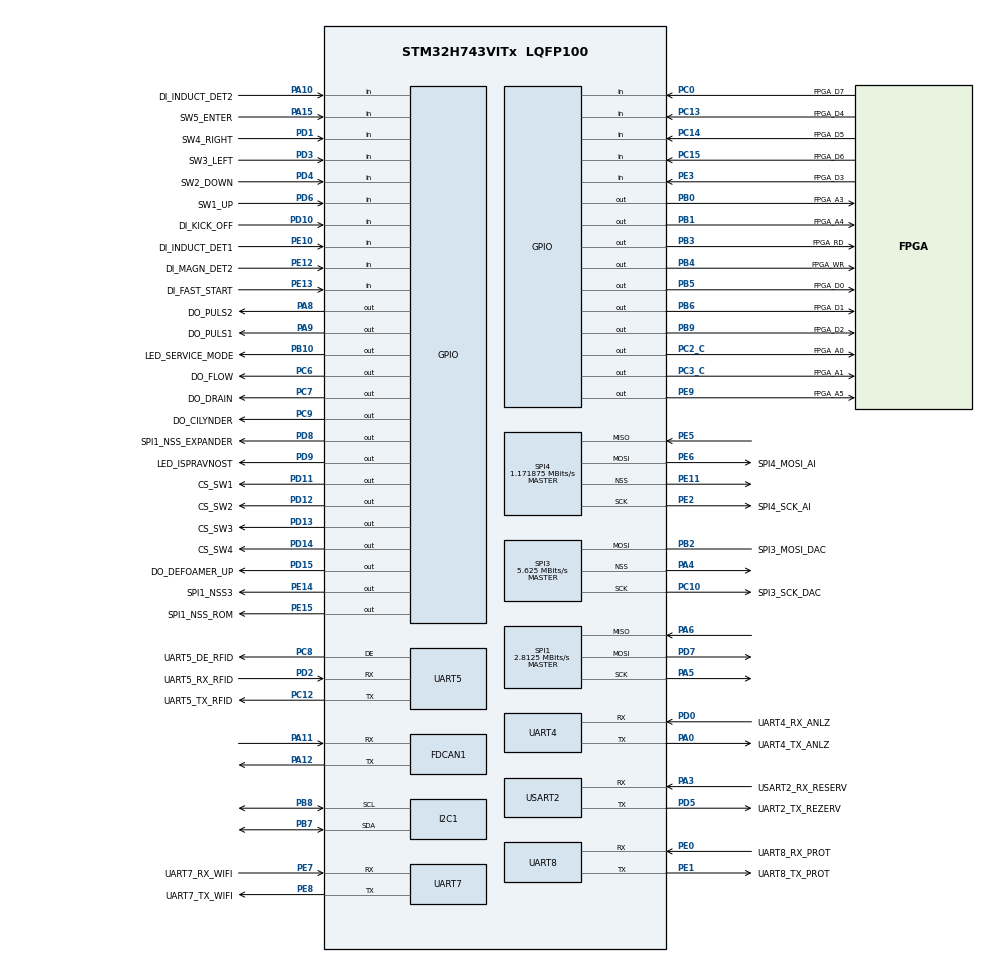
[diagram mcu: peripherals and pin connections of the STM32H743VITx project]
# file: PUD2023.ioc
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Dma.Request0=SPI3_TX
Dma.Request1=SPI4_RX
Dma.Request2=SPI4_TX
Dma.SPI3_TX.0.Direction=DMA_MEMORY_TO_PERIPH
Dma.SPI3_TX.0.EventEnable=DISABLE
Dma.SPI3_TX.0.FIFOMode=DMA_FIFOMODE_DISABLE
Dma.SPI3_TX.0.Instance=DMA1_Stream0
Dma.SPI3_TX.0.MemDataAlignment=DMA_MDATAALIGN_HALFWORD
Dma.SPI3_TX.0.MemInc=DMA_MINC_ENABLE
Dma.SPI3_TX.0.Mode=DMA_CIRCULAR
Dma.SPI3_TX.0.PeriphDataAlignment=DMA_PDATAALIGN_HALFWORD
Dma.SPI3_TX.0.PeriphInc=DMA_PINC_DISABLE
Dma.SPI3_TX.0.Polarity=HAL_DMAMUX_REQ_GEN_RISING
Dma.SPI3_TX.0.Priority=DMA_PRIORITY_LOW
Dma.SPI3_TX.0.RequestNumber=1
Dma.SPI3_TX.0.SignalID=NONE
Dma.SPI3_TX.0.SyncEnable=ENABLE
Dma.SPI3_TX.0.SyncPolarity=HAL_DMAMUX_SYNC_RISING
Dma.SPI3_TX.0.SyncRequestNumber=1
Dma.SPI3_TX.0.SyncSignalID=HAL_DMAMUX1_SYNC_TIM12_TRGO
Dma.SPI4_RX.1.Direction=DMA_PERIPH_TO_MEMORY
Dma.SPI4_RX.1.EventEnable=DISABLE
Dma.SPI4_RX.1.FIFOMode=DMA_FIFOMODE_DISABLE
Dma.SPI4_RX.1.Instance=DMA1_Stream1
Dma.SPI4_RX.1.MemDataAlignment=DMA_MDATAALIGN_BYTE
Dma.SPI4_RX.1.MemInc=DMA_MINC_ENABLE
Dma.SPI4_RX.1.Mode=DMA_NORMAL
Dma.SPI4_RX.1.PeriphDataAlignment=DMA_PDATAALIGN_BYTE
Dma.SPI4_RX.1.PeriphInc=DMA_PINC_DISABLE
Dma.SPI4_RX.1.Polarity=HAL_DMAMUX_REQ_GEN_RISING
Dma.SPI4_RX.1.Priority=DMA_PRIORITY_LOW
Dma.SPI4_RX.1.RequestNumber=1
Dma.SPI4_RX.1.SignalID=NONE
Dma.SPI4_RX.1.SyncEnable=DISABLE
Dma.SPI4_RX.1.SyncPolarity=HAL_DMAMUX_SYNC_NO_EVENT
Dma.SPI4_RX.1.SyncRequestNumber=1
Dma.SPI4_RX.1.SyncSignalID=NONE
Dma.SPI4_TX.2.Direction=DMA_MEMORY_TO_PERIPH
Dma.SPI4_TX.2.EventEnable=DISABLE
Dma.SPI4_TX.2.FIFOMode=DMA_FIFOMODE_DISABLE
Dma.SPI4_TX.2.Instance=DMA1_Stream2
Dma.SPI4_TX.2.MemDataAlignment=DMA_MDATAALIGN_BYTE
Dma.SPI4_TX.2.MemInc=DMA_MINC_ENABLE
Dma.SPI4_TX.2.Mode=DMA_NORMAL
Dma.SPI4_TX.2.PeriphDataAlignment=DMA_PDATAALIGN_BYTE
Dma.SPI4_TX.2.PeriphInc=DMA_PINC_DISABLE
Dma.SPI4_TX.2.Polarity=HAL_DMAMUX_REQ_GEN_RISING
Dma.SPI4_TX.2.Priority=DMA_PRIORITY_LOW
Dma.SPI4_TX.2.RequestNumber=1
Dma.SPI4_TX.2.SignalID=NONE
Dma.SPI4_TX.2.SyncEnable=DISABLE
Dma.SPI4_TX.2.SyncPolarity=HAL_DMAMUX_SYNC_NO_EVENT
Dma.SPI4_TX.2.SyncRequestNumber=1
Dma.SPI4_TX.2.SyncSignalID=NONE
FDCAN1.CalculateBaudRateNominal=1000000
FDCAN1.CalculateTimeBitNominal=1000
FDCAN1.CalculateTimeQuantumNominal=50.0
FDCAN1.Mode=FDCAN_MODE_INTERNAL_LOOPBACK
FDCAN1.NominalPrescaler=2
FDCAN1.NominalTimeSeg1=15
FDCAN1.NominalTimeSeg2=4
FDCAN1.RxFifo0ElmtsNbr=64
FDCAN1.TxFifoQueueElmtsNbr=32
FDCAN1.TxFifoQueueMode=FDCAN_TX_QUEUE_OPERATION
I2C1.Timing=0x109093DC
Mcu.Family=STM32H7
Mcu.Name=STM32H743VITx
Mcu.Package=LQFP100
NVIC.DMA1_Stream0_IRQn=true\:0\:0\:false\:false\:true\:false\:true\:true
NVIC.DMA1_Stream1_IRQn=true\:0\:0\:false\:false\:true\:false\:true\:true
NVIC.DMA1_Stream2_IRQn=true\:0\:0\:false\:false\:true\:false\:true\:true
NVIC.DMAMUX1_OVR_IRQn=true\:0\:0\:false\:false\:true\:false\:true\:true
NVIC.FDCAN1_IT0_IRQn=true\:0\:0\:false\:false\:true\:true\:true\:true
NVIC.FDCAN1_IT1_IRQn=true\:0\:0\:false\:false\:true\:true\:true\:true
NVIC.PriorityGroup=NVIC_PRIORITYGROUP_4
NVIC.SPI3_IRQn=true\:0\:0\:false\:false\:true\:false\:true\:true
NVIC.SPI4_IRQn=true\:0\:0\:false\:false\:true\:false\:true\:true
NVIC.TIM16_IRQn=true\:0\:0\:false\:false\:true\:true\:true\:true
NVIC.TIM7_IRQn=true\:0\:0\:false\:false\:true\:true\:true\:true
PA0.GPIO_Label=UART4_TX_ANLZ
PA0.Mode=Asynchronous
PA0.Signal=UART4_TX
PA10.GPIO_Label=DI_INDUCT_DET2
PA10.Signal=GPIO_Input
PA11.Mode=FDCAN_Activate
PA11.Signal=FDCAN1_RX
PA12.Mode=FDCAN_Activate
PA12.Signal=FDCAN1_TX
PA13\ (JTMS/SWDIO).GPIO_Label=SWDIO_CAN_EN
PA13\ (JTMS/SWDIO).Mode=Serial_Wire
PA13\ (JTMS/SWDIO).Signal=DEBUG_JTMS-SWDIO
PA14\ (JTCK/SWCLK).GPIO_Label=SWCLK
PA14\ (JTCK/SWCLK).Mode=Serial_Wire
PA14\ (JTCK/SWCLK).Signal=DEBUG_JTCK-SWCLK
PA15\ (JTDI).GPIO_Label=SW5_ENTER
PA15\ (JTDI).Signal=GPIO_Input
PA3.GPIO_Label=USART2_RX_RESERV
PA3.Mode=Asynchronous
PA3.Signal=USART2_RX
PA4.Mode=NSS_Signal_Hard_Output
PA4.Signal=SPI3_NSS
PA5.Mode=Full_Duplex_Master
PA5.Signal=SPI1_SCK
PA6.Mode=Full_Duplex_Master
PA6.Signal=SPI1_MISO
PA8.GPIO_Label=DO_PULS2
PA8.Signal=GPIO_Output
PA9.GPIO_Label=DO_PULS1
PA9.Signal=GPIO_Output
PB0.GPIO_Label=FPGA_A3
PB0.Signal=GPIO_Output
PB1.GPIO_Label=FPGA_A4
PB1.Signal=GPIO_Output
PB10.GPIO_Label=LED_SERVICE_MODE
PB10.Signal=GPIO_Output
PB2.GPIO_Label=SPI3_MOSI_DAC
PB2.Mode=Simplex_Bidirectional_Master
PB2.Signal=SPI3_MOSI
PB3\ (JTDO/TRACESWO).GPIO_Label=FPGA_RD
PB3\ (JTDO/TRACESWO).Signal=GPIO_Output
PB4\ (NJTRST).GPIO_Label=FPGA_WR
PB4\ (NJTRST).Signal=GPIO_Output
PB5.GPIO_Label=FPGA_D0
PB5.Signal=GPIO_Output
PB6.GPIO_Label=FPGA_D1
PB6.Signal=GPIO_Output
PB7.GPIO_Pu=GPIO_PULLUP
PB7.Mode=I2C
PB7.Signal=I2C1_SDA
PB8.GPIO_Pu=GPIO_PULLUP
PB8.Mode=I2C
PB8.Signal=I2C1_SCL
PB9.GPIO_Label=FPGA_D2
PB9.Signal=GPIO_Output
PC0.GPIO_Label=FPGA_D7
PC0.Signal=GPIO_Input
PC10.GPIO_Label=SPI3_SCK_DAC
PC10.Mode=Simplex_Bidirectional_Master
PC10.Signal=SPI3_SCK
PC12.GPIO_Label=UART5_TX_RFID
PC12.Mode=Asynchronous
PC12.Signal=UART5_TX
PC13.GPIO_Label=FPGA_D4
PC13.Signal=GPIO_Input
PC14-OSC32_IN\ (OSC32_IN).GPIO_Label=FPGA_D5
PC14-OSC32_IN\ (OSC32_IN).Signal=GPIO_Input
PC15-OSC32_OUT\ (OSC32_OUT).GPIO_Label=FPGA_D6
PC15-OSC32_OUT\ (OSC32_OUT).Signal=GPIO_Input
PC2_C.GPIO_Label=FPGA_A0
PC2_C.Signal=GPIO_Output
PC3_C.GPIO_Label=FPGA_A1
PC3_C.Signal=GPIO_Output
PC6.GPIO_Label=DO_FLOW
PC6.Signal=GPIO_Output
PC7.GPIO_Label=DO_DRAIN
PC7.Signal=GPIO_Output
PC8.GPIO_Label=UART5_DE_RFID
PC8.Mode=Hardware Flow Control (RS485)
PC8.Signal=UART5_DE
PC9.GPIO_Label=DO_CILYNDER
PC9.Signal=GPIO_Output
PD0.GPIO_Label=UART4_RX_ANLZ
PD0.Mode=Asynchronous
PD0.Signal=UART4_RX
PD1.GPIO_Label=SW4_RIGHT
PD1.Signal=GPIO_Input
PD10.GPIO_Label=DI_KICK_OFF
PD10.Signal=GPIO_Input
PD11.GPIO_Label=CS_SW1
PD11.Signal=GPIO_Output
PD12.GPIO_Label=CS_SW2
PD12.Signal=GPIO_Output
PD13.GPIO_Label=CS_SW3
PD13.Signal=GPIO_Output
PD14.GPIO_Label=CS_SW4
PD14.Signal=GPIO_Output
PD15.GPIO_Label=DO_DEFOAMER_UP
PD15.Signal=GPIO_Output
PD2.GPIO_Label=UART5_RX_RFID
PD2.Mode=Asynchronous
PD2.Signal=UART5_RX
PD3.GPIO_Label=SW3_LEFT
PD3.Signal=GPIO_Input
PD4.GPIO_Label=SW2_DOWN
PD4.Signal=GPIO_Input
PD5.GPIO_Label=UART2_TX_REZERV
PD5.Mode=Asynchronous
PD5.Signal=USART2_TX
PD6.GPIO_Label=SW1_UP
PD6.Signal=GPIO_Input
PD7.Mode=Full_Duplex_Master
PD7.Signal=SPI1_MOSI
PD8.GPIO_Label=SPI1_NSS_EXPANDER
PD8.Signal=GPIO_Output
PD9.GPIO_Label=LED_ISPRAVNOST
PD9.Signal=GPIO_Output
PE0.GPIO_Label=UART8_RX_PROT
PE0.Mode=Asynchronous
PE0.Signal=UART8_RX
PE1.GPIO_Label=UART8_TX_PROT
PE1.Mode=Asynchronous
PE1.Signal=UART8_TX
PE10.GPIO_Label=DI_INDUCT_DET1
PE10.Signal=GPIO_Input
PE11.Mode=NSS_Signal_Hard_Output
PE11.Signal=SPI4_NSS
PE12.GPIO_Label=DI_MAGN_DET2
PE12.Signal=GPIO_Input
PE13.GPIO_Label=DI_FAST_START
PE13.Signal=GPIO_Input
PE14.GPIO_Label=SPI1_NSS3
PE14.PinState=GPIO_PIN_SET
PE14.Signal=GPIO_Output
PE15.GPIO_Label=SPI1_NSS_ROM
PE15.Signal=GPIO_Output
PE2.GPIO_Label=SPI4_SCK_AI
PE2.Mode=Full_Duplex_Master
PE2.Signal=SPI4_SCK
PE3.GPIO_Label=FPGA_D3
PE3.Signal=GPIO_Input
PE5.Mode=Full_Duplex_Master
PE5.Signal=SPI4_MISO
PE6.GPIO_Label=SPI4_MOSI_AI
PE6.Mode=Full_Duplex_Master
PE6.Signal=SPI4_MOSI
PE7.GPIO_Label=UART7_RX_WIFI
PE7.Mode=Asynchronous
PE7.Signal=UART7_RX
PE8.GPIO_Label=UART7_TX_WIFI
PE8.Mode=Asynchronous
PE8.Signal=UART7_TX
PE9.GPIO_Label=FPGA_A5
PE9.Signal=GPIO_Output
PH0-OSC_IN\ (PH0).Mode=HSE-External-Oscillator
PH0-OSC_IN\ (PH0).Signal=RCC_OSC_IN
PH1-OSC_OUT\ (PH1).Mode=HSE-External-Oscillator
PH1-OSC_OUT\ (PH1).Signal=RCC_OSC_OUT
ProjectManager.HeapSize=0x8000
ProjectManager.StackSize=0x4000
ProjectManager.TargetToolchain=EWARM V8.50
RCC.ADCFreq_Value=80000000
RCC.APB1Freq_Value=112500000
RCC.APB2Freq_Value=112500000
RCC.APB3Freq_Value=112500000
RCC.APB4Freq_Value=112500000
RCC.CortexFreq_Value=450000000
RCC.D1PPRE=RCC_APB3_DIV2
RCC.D2PPRE1=RCC_APB1_DIV2
RCC.D2PPRE2=RCC_APB2_DIV2
RCC.D3PPRE=RCC_APB4_DIV2
RCC.DIVM1=2
RCC.DIVM2=5
RCC.DIVM3=2
RCC.DIVN1=72
RCC.DIVN2=32
RCC.DIVN3=12
RCC.DIVQ1=5
RCC.DIVQ2=4
RCC.FDCANCLockSelection=RCC_FDCANCLKSOURCE_PLL2
RCC.HCLKFreq_Value=225000000
RCC.HPRE=RCC_HCLK_DIV2
RCC.I2C123CLockSelection=RCC_I2C123CLKSOURCE_PLL3
RCC.PLL2FRACN=0
RCC.PLL3FRACN=0
RCC.PLLFRACN=0
RCC.PLLSourceVirtual=RCC_PLLSOURCE_HSE
RCC.SYSCLKFreq_VALUE=450000000
RCC.SYSCLKSource=RCC_SYSCLKSOURCE_PLLCLK
RCC.Spi45ClockSelection=RCC_SPI45CLKSOURCE_PLL3
RCC.USBFreq_Value=180000000
SPI1.BaudRatePrescaler=SPI_BAUDRATEPRESCALER_64
SPI1.CLKPhase=SPI_PHASE_2EDGE
SPI1.CalculateBaudRate=2.8125 MBits/s
SPI1.DataSize=SPI_DATASIZE_16BIT
SPI1.Direction=SPI_DIRECTION_2LINES
SPI1.Mode=SPI_MODE_MASTER
SPI1.VirtualType=VM_MASTER
SPI3.BaudRatePrescaler=SPI_BAUDRATEPRESCALER_32
SPI3.CalculateBaudRate=5.625 MBits/s
SPI3.DataSize=SPI_DATASIZE_16BIT
SPI3.Direction=SPI_DIRECTION_1LINE
SPI3.Mode=SPI_MODE_MASTER
SPI3.VirtualNSS=VM_NSSHARD
SPI3.VirtualType=VM_MASTER
SPI4.BaudRatePrescaler=SPI_BAUDRATEPRESCALER_64
SPI4.CLKPhase=SPI_PHASE_1EDGE
SPI4.CLKPolarity=SPI_POLARITY_LOW
SPI4.CalculateBaudRate=1.171875 MBits/s
SPI4.DataSize=SPI_DATASIZE_8BIT
SPI4.Direction=SPI_DIRECTION_2LINES
SPI4.Mode=SPI_MODE_MASTER
SPI4.VirtualNSS=VM_NSSHARD
SPI4.VirtualType=VM_MASTER
TIM12.AutoReloadPreload=TIM_AUTORELOAD_PRELOAD_ENABLE
TIM12.Channel-Output\ Compare1\ No\ Output=TIM_CHANNEL_1
TIM12.Period=2510
TIM12.TIM_MasterOutputTrigger=TIM_TRGO_UPDATE
TIM16.AutoReloadPreload=TIM_AUTORELOAD_PRELOAD_ENABLE
TIM16.Channel=TIM_CHANNEL_1
TIM16.ClockDivision=TIM_CLOCKDIVISION_DIV4
TIM16.Period=10
TIM16.Prescaler=56250
TIM7.AutoReloadPreload=TIM_AUTORELOAD_PRELOAD_ENABLE
TIM7.Period=22590
TIM7.TIM_MasterOutputTrigger=TIM_TRGO_UPDATE
USART2.VirtualMode-Asynchronous=VM_ASYNC
VP_MEMORYMAP_VS_MEMORYMAP.Mode=CurAppReg
VP_TIM12_VS_ClockSourceINT.Mode=Internal
VP_TIM12_VS_no_output1.Mode=Output Compare1 No Output
VP_TIM16_VS_ClockSourceINT.Mode=Enable_Timer
VP_TIM16_VS_no_output1.Mode=Output Compare1 No Output
VP_TIM7_VS_ClockSourceINT.Mode=Enable_Timer
board=custom

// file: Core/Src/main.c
/* USER CODE BEGIN Header */
/**
  *********************************************************************************************
  * @file           : main.c
  * @brief          : Main program body
  * @author         : Artur Petrosyan
  * @date           : 10/04/2024
  * @date           :
  *
  * @note
  *
  * Программа системы ILS
  *
  *********************************************************************************************
  */

/**
  *********************************************************************************************
  * @History
  * @date     :
  *
  *********************************************************************************************
  */
/* USER CODE END Header */
#include "main.h"
#include "dma.h"
#include "fdcan.h"
#include "i2c.h"
#include "memorymap.h"
#include "spi.h"
#include "tim.h"
#include "usart.h"
#include "gpio.h"

/* USER CODE BEGIN Includes */
#include "pud.h"
#include "tle7230.h"
/* USER CODE END Includes */

/* USER CODE BEGIN PV */
DMA_BUFFER uint16_t TON4980[TON4980_POINT_NUM];
DMA_BUFFER uint8_t adc_data[ADC_BUF_SIZE];
PUD_t PUD;
/* USER CODE END PV */

void SystemClock_Config(void);
void PeriphCommonClock_Config(void);
/* USER CODE BEGIN PFP */
static void TON4980_Calc (uint16_t *dest, uint16_t point_num);
/* USER CODE END PFP */

int main(void)
{

  /* MCU Configuration--------------------------------------------------------*/

  /* Reset of all peripherals, Initializes the Flash interface and the Systick. */
  HAL_Init();

  /* Configure the system clock */
  SystemClock_Config();

  /* Configure the peripherals common clocks */
  PeriphCommonClock_Config();

  /* Initialize all configured peripherals */
  MX_GPIO_Init();
  MX_DMA_Init();
  MX_SPI1_Init();
  MX_SPI3_Init();
  MX_UART4_Init();
  MX_UART5_Init();
  MX_UART7_Init();
  MX_UART8_Init();
  MX_USART2_UART_Init();
  MX_SPI4_Init();
  MX_I2C1_Init();
  MX_TIM16_Init();
  MX_FDCAN1_Init();
  MX_TIM12_Init();
  MX_TIM7_Init();
  /* USER CODE BEGIN 2 */
  TON4980_Calc(TON4980, TON4980_POINT_NUM);
  PUD_Init();
  TLE7230_Init();
  BTS716G(BTS716G_7, BTS716G_OUT_1, BTS716G_OFF);
  BTS716G(BTS716G_7, BTS716G_OUT_2, BTS716G_OFF);
  BTS716G(BTS716G_7, BTS716G_OUT_4, BTS716G_OFF);
  BTS716G(BTS716G_8, BTS716G_OUT_1, BTS716G_OFF);
  BTS716G(BTS716G_8, BTS716G_OUT_2, BTS716G_OFF);
  BTS716G(BTS716G_8, BTS716G_OUT_3, BTS716G_OFF);

  HAL_FDCAN_ConfigInterruptLines (&hfdcan1, FDCAN_IT_RX_FIFO0_NEW_MESSAGE, FDCAN_INTERRUPT_LINE0);
  HAL_FDCAN_ActivateNotification (&hfdcan1, FDCAN_IT_RX_FIFO0_NEW_MESSAGE, 0);

  HAL_FDCAN_Start(&hfdcan1);
  CAN_SelfTest();
  AO2_EN();
  CS_SW3_EN();

  // Включаем нерхний зонд. Нижний выключаем.
//  CS_SW1_DIS();
//  CS_SW2_EN();

  // Включаем нижний зонд. Верхний выключаем.
  CS_SW1_EN();
  CS_SW2_DIS();

  PUD.milk_counter = 0;
  PUD.start_milking_btn = 0;
  TON4980_Start(TON4980);

  /* USER CODE END 2 */

  /* Infinite loop */
  /* USER CODE BEGIN WHILE */
  while (1)
  {
      HAL_GPIO_TogglePin(LED_ISPRAVNOST_GPIO_Port, LED_ISPRAVNOST_Pin);
      HAL_Delay(300);

      PUD.start_milking_btn = Start_Milking_Button();

    /* USER CODE END WHILE */

  }
}

void SystemClock_Config(void)
{
  RCC_OscInitTypeDef RCC_OscInitStruct = {0};
  RCC_ClkInitTypeDef RCC_ClkInitStruct = {0};

  /** Supply configuration update enable
  */
  HAL_PWREx_ConfigSupply(PWR_LDO_SUPPLY);

  /** Configure the main internal regulator output voltage
  */
  __HAL_PWR_VOLTAGESCALING_CONFIG(PWR_REGULATOR_VOLTAGE_SCALE1);

  while(!__HAL_PWR_GET_FLAG(PWR_FLAG_VOSRDY)) {}

  __HAL_RCC_SYSCFG_CLK_ENABLE();
  __HAL_PWR_VOLTAGESCALING_CONFIG(PWR_REGULATOR_VOLTAGE_SCALE0);

  while(!__HAL_PWR_GET_FLAG(PWR_FLAG_VOSRDY)) {}

  /** Initializes the RCC Oscillators according to the specified parameters
  * in the RCC_OscInitTypeDef structure.
  */
  RCC_OscInitStruct.OscillatorType = RCC_OSCILLATORTYPE_HSE;
  RCC_OscInitStruct.HSEState = RCC_HSE_ON;
  RCC_OscInitStruct.PLL.PLLState = RCC_PLL_ON;
  RCC_OscInitStruct.PLL.PLLSource = RCC_PLLSOURCE_HSE;
  RCC_OscInitStruct.PLL.PLLM = 2;
  RCC_OscInitStruct.PLL.PLLN = 72;
  RCC_OscInitStruct.PLL.PLLP = 2;
  RCC_OscInitStruct.PLL.PLLQ = 5;
  RCC_OscInitStruct.PLL.PLLR = 2;
  RCC_OscInitStruct.PLL.PLLRGE = RCC_PLL1VCIRANGE_3;
  RCC_OscInitStruct.PLL.PLLVCOSEL = RCC_PLL1VCOWIDE;
  RCC_OscInitStruct.PLL.PLLFRACN = 0;
  if (HAL_RCC_OscConfig(&RCC_OscInitStruct) != HAL_OK)
  {
    Error_Handler();
  }

  /** Initializes the CPU, AHB and APB buses clocks
  */
  RCC_ClkInitStruct.ClockType = RCC_CLOCKTYPE_HCLK|RCC_CLOCKTYPE_SYSCLK
                              |RCC_CLOCKTYPE_PCLK1|RCC_CLOCKTYPE_PCLK2
                              |RCC_CLOCKTYPE_D3PCLK1|RCC_CLOCKTYPE_D1PCLK1;
  RCC_ClkInitStruct.SYSCLKSource = RCC_SYSCLKSOURCE_PLLCLK;
  RCC_ClkInitStruct.SYSCLKDivider = RCC_SYSCLK_DIV1;
  RCC_ClkInitStruct.AHBCLKDivider = RCC_HCLK_DIV2;
  RCC_ClkInitStruct.APB3CLKDivider = RCC_APB3_DIV2;
  RCC_ClkInitStruct.APB1CLKDivider = RCC_APB1_DIV2;
  RCC_ClkInitStruct.APB2CLKDivider = RCC_APB2_DIV2;
  RCC_ClkInitStruct.APB4CLKDivider = RCC_APB4_DIV2;

  if (HAL_RCC_ClockConfig(&RCC_ClkInitStruct, FLASH_LATENCY_3) != HAL_OK)
  {
    Error_Handler();
  }
}

void PeriphCommonClock_Config(void)
{
  RCC_PeriphCLKInitTypeDef PeriphClkInitStruct = {0};

  /** Initializes the peripherals clock
  */
  PeriphClkInitStruct.PeriphClockSelection = RCC_PERIPHCLK_I2C1|RCC_PERIPHCLK_SPI4;
  PeriphClkInitStruct.PLL3.PLL3M = 2;
  PeriphClkInitStruct.PLL3.PLL3N = 12;
  PeriphClkInitStruct.PLL3.PLL3P = 2;
  PeriphClkInitStruct.PLL3.PLL3Q = 2;
  PeriphClkInitStruct.PLL3.PLL3R = 2;
  PeriphClkInitStruct.PLL3.PLL3RGE = RCC_PLL3VCIRANGE_3;
  PeriphClkInitStruct.PLL3.PLL3VCOSEL = RCC_PLL3VCOMEDIUM;
  PeriphClkInitStruct.PLL3.PLL3FRACN = 0;
  PeriphClkInitStruct.Spi45ClockSelection = RCC_SPI45CLKSOURCE_PLL3;
  PeriphClkInitStruct.I2c123ClockSelection = RCC_I2C123CLKSOURCE_PLL3;
  if (HAL_RCCEx_PeriphCLKConfig(&PeriphClkInitStruct) != HAL_OK)
  {
    Error_Handler();
  }
}

/* USER CODE BEGIN 4 */
/**
 *********************************************************************************************
 * @brief Callback функция. Переключает ключ в нуле каждой полуволны 4980 Гц
 *
 * @param [] - None
 * @retval [] - None
 *
 * @note
 *
 *********************************************************************************************
*/
void HAL_SPI_TxHalfCpltCallback (SPI_HandleTypeDef *hspi)
{
    /* Переключаем ключ в нуле каждой полуволны 4980 Гц */
    if (hspi->Instance == SPI3) {
        TOGGLE_SW4();
    }
}

/**
 *********************************************************************************************
 * @brief Callback функция. После оцифровки ADC_BUF_SIZE сигнала проточного датчика молока
 *        вызывает обработчик сигнала.
 *
 * @param [] - None
 * @retval [] - None
 *
 * @note
 *
 *********************************************************************************************
*/
void HAL_SPI_TxCpltCallback (SPI_HandleTypeDef *hspi)
{
    /* Переключаем ключ в нуле каждой полуволны 4980 Гц */
    if (hspi->Instance == SPI3) {
        TOGGLE_SW4();
    }
}

/**
 *********************************************************************************************
 * @brief Callback функция. После оцифровки ADC_BUF_SIZE сигнала проточного датчика молока
 *        вызывает обработчик сигнала.
 *
 * @param [] - None
 * @retval [] - None
 *
 * @note
 *
 *********************************************************************************************
*/
void HAL_SPI_RxCpltCallback (SPI_HandleTypeDef *hspi)
{

    if (hspi->Instance == SPI4) {

    }
}

void HAL_SPI_TxRxCpltCallback (SPI_HandleTypeDef *hspi)
{
    if (hspi->Instance == SPI4) {
        /* Здесь включаем модуль SPI4, т.к. HAL его выключает после приема/передачи, а мы используем аппаратный NSS */
      __HAL_SPI_ENABLE(&ADC_SPI);
    }
}

/**
 *********************************************************************************************
 * @brief Callback функция. Запускает преобразование внешнего АЦП
 *
 * @param [] - None
 * @retval [] - None
 *
 * @note
 *
 *********************************************************************************************
*/
void HAL_TIM_PeriodElapsedCallback (TIM_HandleTypeDef *htim)
{
    static const uint8_t adc_tx_data[3] = {0b00000111, 0b00000000, 0};
    static uint32_t i = 0;
    static uint32_t j = 0;
    HAL_StatusTypeDef st;

    // Петриод переключения электродов датчика. Равен EPERIOD * 0.01s. Где 0.01s период тамера TIM16
    const uint32_t EPERIOD = 100;

    if (htim->Instance == TIM16) {
        /* Включаем АЦП. Используется аппаратный NSS */
        if (i > (ADC_BUF_SIZE - 3)) i = 0;
        st = HAL_SPI_TransmitReceive_DMA(&ADC_SPI, (uint8_t *)&adc_tx_data[0], (uint8_t *)&adc_data[i], 3);
        if (st == HAL_OK) {
            i += 3;
        }

        if (j >= EPERIOD) {
            TOGGLE_SW1();
            TOGGLE_SW2();
            /* Обработка оцифрованного сигнала проточного дататчика молока */
            MilkSensor_Process(adc_data, &PUD.milk_counter);
            j = 0;
        } else {
            j++;
        }
    } else if (htim->Instance == TIM7) {
//        TOGGLE_SW4();
    }
}

/**
 *********************************************************************************************
 * @brief Сервисная функция генерации отсчетов тонального сигнала частотой 4980 Гц
 *
 * @param [dest]      Указатель на массив для сохранения результата
 * @param [point_num] Требуемое число отсчетов на период
 *
 * @retval [] None
 *
 * @note
 *
 *********************************************************************************************
*/
static void TON4980_Calc (uint16_t *dest, uint16_t point_num)
{
  /* Это расчет отсчетов тонального сигнала маркерного приемника. В окончательном варианте удалить */
  float k;
  const uint16_t Am = 16384;
  const float Ph = 0.4f;
  uint32_t t;

  k = (2* 3.1415926535897932384626433832795f) / point_num;
  for (t = 0; t < point_num; t++) {
      dest[t] = (uint16_t)((Am-1)*(sin(k * t + Ph)) + Am);
  }
}
/* USER CODE END 4 */

void Error_Handler(void)
{
  __disable_irq();
  while (1)
  {
  }
}
